# STM32G534 register map
File version: 2.0.0
CPU: CM33 r0p4, little endian, MPU, FPU, 4 interrupt priority bits
Registers are 32-bit, read-write, reset 0x0 unless marked. A register's access mark holds for its fields unless they carry their own. Offsets are from the block's base; [hi:lo] are bit positions; {n}, {i} and the like mark numbered series; 'fields as' and 'values as' point back to an identical list.

## GTZC1_TZSC — GTZC1_TZSC register block
Base 0x40032400
Same registers: GTZC1_TZSC_S 0x50032400
0x00 TZSC_CR — TZSC control register
  [0] LCK — lock the configuration of GTZC1_TZSC_SECCFGRx and GTZC1_TZSC_PRIVCFGRx until next reset
    0=configuration of all GTZC1_TZSC_SECCFGRx and GTZC1_TZSC_PRIVCFGRx not locked; 1=configuration of all GTZC1_TZSC_SECCFGRx and GTZC1_TZSC_PRIVCFGRx locked
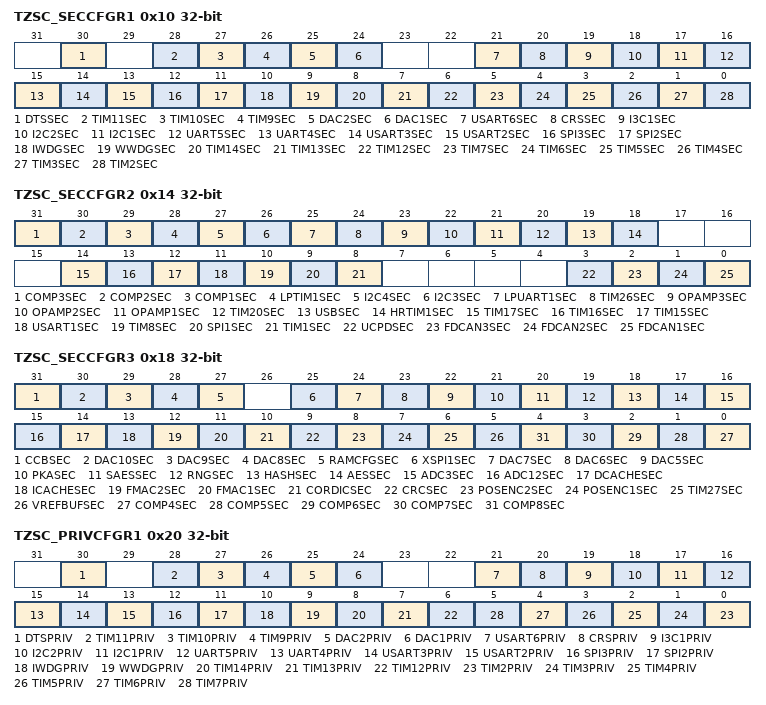
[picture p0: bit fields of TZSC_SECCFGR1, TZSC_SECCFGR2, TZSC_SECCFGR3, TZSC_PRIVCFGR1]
0x10 TZSC_SECCFGR1 — TZSC secure configuration register 1
  [30] DTSSEC — secure access mode for DTS
    0=nonsecure; 1=secure
  [28] TIM11SEC — secure access mode for TIM11
    0=nonsecure; 1=secure
  [27] TIM10SEC — secure access mode for TIM10
    0=nonsecure; 1=secure
  [26] TIM9SEC — secure access mode for TIM9
    0=nonsecure; 1=secure
  [25] DAC2SEC — secure access mode for DAC2
    0=nonsecure; 1=secure
  [24] DAC1SEC — secure access mode for DAC1
    0=nonsecure; 1=secure
  [21] USART6SEC — secure access mode for USART6
    0=nonsecure; 1=secure
  [20] CRSSEC — secure access mode for CRS
    0=nonsecure; 1=secure
  [19] I3C1SEC — secure access mode for I3C1
    0=nonsecure; 1=secure
  [18] I2C2SEC — secure access mode for I2C2
    0=nonsecure; 1=secure
  [17] I2C1SEC — secure access mode for I2C1
    0=nonsecure; 1=secure
  [16] UART5SEC — secure access mode for UART5
    0=nonsecure; 1=secure
  [15] UART4SEC — secure access mode for UART4
    0=nonsecure; 1=secure
  [14] USART3SEC — secure access mode for USART3
    0=nonsecure; 1=securew
  [13] USART2SEC — secure access mode for USART2
    0=nonsecure; 1=secure
  [12] SPI3SEC — secure access mode for SPI3
    0=nonsecure; 1=secure
  [11] SPI2SEC — secure access mode for SPI2
    0=nonsecure; 1=secure
  [10] IWDGSEC — secure access mode for IWDG
    0=nonsecure; 1=secure
  [9] WWDGSEC — secure access mode for WWDG
    0=nonsecure; 1=secure
  [8] TIM14SEC — secure access mode for TIM14
    0=nonsecure; 1=secure
  [7] TIM13SEC — secure access mode for TIM13
    0=nonsecure; 1=secure
  [6] TIM12SEC — secure access mode for TIM12
    0=nonsecure; 1=secure
  [5] TIM7SEC — secure access mode for TIM7
    0=nonsecure; 1=secure
  [4] TIM6SEC — secure access mode for TIM6
    0=nonsecure; 1=secure
  [3] TIM5SEC — secure access mode for TIM5
    0=nonsecure; 1=secure
  [2] TIM4SEC — secure access mode for TIM5
    0=nonsecure; 1=secure
  [1] TIM3SEC — secure access mode for TIM3
    0=nonsecure; 1=secure
  [0] TIM2SEC — secure access mode for TIM2
    0=nonsecure; 1=secure
0x14 TZSC_SECCFGR2 — TZSC secure configuration register 2
  [all] fields
    0=nonsecure; 1=secure
  [31] COMP3SEC — secure access mode for COMP3
  [30] COMP2SEC — secure access mode for COMP2
  [29] COMP1SEC — secure access mode for COMP1
  [28] LPTIM1SEC — secure access mode for LPTIM1
  [27] I2C4SEC — secure access mode for I2C4
  [26] I2C3SEC — secure access mode for I2C3
  [25] LPUART1SEC — secure access mode for LPUART1
  [24] TIM26SEC — secure access mode for TIM26
  [23] OPAMP3SEC — secure access mode for OPAMP3
  [22] OPAMP2SEC — secure access mode for OPAMP2
  [21] OPAMP1SEC — secure access mode for OPAMP1
  [20] TIM20SEC — secure access mode for TIM20
  [19] USBSEC — secure access mode for USB
  [18] HRTIM1SEC — secure access mode for HRTIM1
  [14] TIM17SEC — secure access mode for TIM17
  [13] TIM16SEC — secure access mode for TIM16
  [12] TIM15SEC — secure access mode for TIM15
  [11] USART1SEC — secure access mode for USART1
  [10] TIM8SEC — secure access mode for TIM8
  [9] SPI1SEC — secure access mode for SPI1
  [8] TIM1SEC — secure access mode for TIM1
  [3] UCPDSEC — secure access mode for UCPD
  [2] FDCAN3SEC — secure access mode for FDCAN3
  [1] FDCAN2SEC — secure access mode for FDCAN2
  [0] FDCAN1SEC — secure access mode for FDCAN1
0x18 TZSC_SECCFGR3 — TZSC secure configuration register 3
  [all] fields
    0=nonsecure; 1=secure
  [31] CCBSEC — secure access mode for CCB
  [30] DAC10SEC — secure access mode for DAC10
  [29] DAC9SEC — secure access mode for DAC9
  [28] DAC8SEC — secure access mode for DAC8
  [27] RAMCFGSEC — secure access mode for RAMCFG
  [25] XSPI1SEC — secure access mode for XSPI1
  [24] DAC7SEC — secure access mode for DAC7
  [23] DAC6SEC — secure access mode for DAC6
  [22] DAC5SEC — secure access mode for DAC5
  [21] PKASEC — secure access mode for PKA
  [20] SAESSEC — secure access mode for SAES
  [19] RNGSEC — secure access mode for RNG
  [18] HASHSEC — secure access mode for HASH
  [17] AESSEC — secure access mode for AES
  [16] ADC3SEC — secure access mode for ADC3
  [15] ADC12SEC — secure access mode for ADC1 and ADC2
  [14] DCACHESEC — secure access mode for DCACHE
  [13] ICACHESEC — secure access mode for ICACHE
  [12] FMAC2SEC — secure access mode for register of FMAC2
  [11] FMAC1SEC — secure access mode for register of FMAC1
  [10] CORDICSEC — secure access mode for CORDIC
  [9] CRCSEC — secure access mode for CRC
  [8] POSENC2SEC — secure access mode for POSENC2
  [7] POSENC1SEC — secure access mode for POSENC1
  [6] TIM27SEC — secure access mode for TIM27
  [5] VREFBUFSEC — secure access mode for VREFBUF
  [n-4] COMP{n}SEC (n=4..8) — secure access mode for COMP{n}
0x20 TZSC_PRIVCFGR1 — TZSC privilege configuration register 1
  [all] fields
    0=unprivileged; 1=privileged
  [30] DTSPRIV — privileged access mode for DTS
  [28] TIM11PRIV — privileged access mode for TIM11
  [27] TIM10PRIV — privileged access mode for TIM10
  [26] TIM9PRIV — privileged access mode for TIM9
  [25] DAC2PRIV — privileged access mode for DAC2
  [24] DAC1PRIV — privileged access mode for DAC1
  [21] USART6PRIV — privileged access mode for USART6
  [20] CRSPRIV — privileged access mode for CRS
  [19] I3C1PRIV — privileged access mode for I3C1
  [18] I2C2PRIV — privileged access mode for I2C2
  [17] I2C1PRIV — privileged access mode for I2C1
  [16] UART5PRIV — privileged access mode for UART5
  [15] UART4PRIV — privileged access mode for UART4
  [14] USART3PRIV — privileged access mode for USART3
  [13] USART2PRIV — privileged access mode for USART2
  [12] SPI3PRIV — privileged access mode for SPI3
  [11] SPI2PRIV — privileged access mode for SPI2
  [10] IWDGPRIV — privileged access mode for IWDG
  [9] WWDGPRIV — privileged access mode for WWDG
  [8] TIM14PRIV — privileged access mode for TIM14
  [7] TIM13PRIV — privileged access mode for TIM13
  [6] TIM12PRIV — privileged access mode for TIM12
  [n-2] TIM{n}PRIV (n=2..7) — privileged access mode for TIM{n}
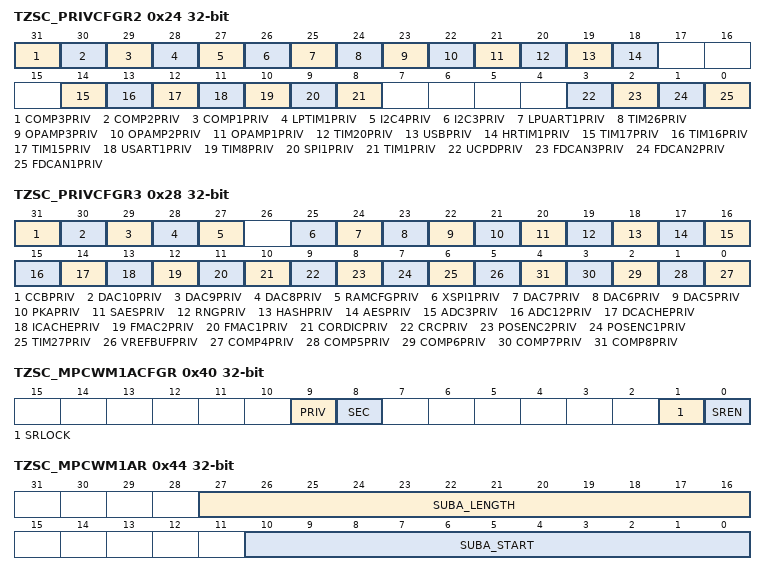
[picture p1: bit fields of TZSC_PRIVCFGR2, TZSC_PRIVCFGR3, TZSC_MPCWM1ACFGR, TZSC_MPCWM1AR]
0x24 TZSC_PRIVCFGR2 — TZSC privilege configuration register 2
  [all] fields
    0=unprivileged; 1=privileged
  [31] COMP3PRIV — privileged access mode for COMP3
  [30] COMP2PRIV — privileged access mode for COMP2
  [29] COMP1PRIV — privileged access mode for COMP1
  [28] LPTIM1PRIV — privileged access mode for LPTIM1
  [27] I2C4PRIV — privileged access mode for I2C4
  [26] I2C3PRIV — privileged access mode for I2C3
  [25] LPUART1PRIV — privileged access mode for LPUART1
  [24] TIM26PRIV — privileged access mode for TIM26
  [23] OPAMP3PRIV — privileged access mode for OPAMP3
  [22] OPAMP2PRIV — privileged access mode for OPAMP2
  [21] OPAMP1PRIV — privileged access mode for OPAMP1
  [20] TIM20PRIV — privileged access mode for TIM20
  [19] USBPRIV — privileged access mode for USB
  [18] HRTIM1PRIV — privileged access mode for HRTIM1
  [14] TIM17PRIV — privileged access mode for TIM17
  [13] TIM16PRIV — privileged access mode for TIM16
  [12] TIM15PRIV — privileged access mode for TIM15
  [11] USART1PRIV — privileged access mode for USART1
  [10] TIM8PRIV — privileged access mode for TIM8
  [9] SPI1PRIV — privileged access mode for SPI1
  [8] TIM1PRIV — privileged access mode for TIM1
  [3] UCPDPRIV — privileged access mode for UCPD
  [2] FDCAN3PRIV — privileged access mode for FDCAN3
  [1] FDCAN2PRIV — privileged access mode for FDCAN2
  [0] FDCAN1PRIV — privileged access mode for FDCAN1
0x28 TZSC_PRIVCFGR3 — TZSC privilege configuration register 3
  [all] fields
    0=unprivileged; 1=privileged
  [31] CCBPRIV — privileged access mode for CCB
  [30] DAC10PRIV — privileged access mode for DAC10
  [29] DAC9PRIV — privileged access mode for DAC9
  [28] DAC8PRIV — privileged access mode for DAC8
  [27] RAMCFGPRIV — privileged access mode for RAMCFG
  [25] XSPI1PRIV — privileged access mode for XSPI1
  [24] DAC7PRIV — privileged access mode for DAC7
  [23] DAC6PRIV — privileged access mode for DAC6
  [22] DAC5PRIV — privileged access mode for DAC5
  [21] PKAPRIV — privileged access mode for PKA
  [20] SAESPRIV — privileged access mode for SAES
  [19] RNGPRIV — privileged access mode for RNG
  [18] HASHPRIV — privileged access mode for HASH
  [17] AESPRIV — privileged access mode for AES
  [16] ADC3PRIV — privileged access mode for ADC3
  [15] ADC12PRIV — privileged access mode for ADC1 and ADC2
  [14] DCACHEPRIV — privileged access mode for DCACHE
  [13] ICACHEPRIV — privileged access mode for ICACHE
  [12] FMAC2PRIV — privileged access mode for register of FMAC2
  [11] FMAC1PRIV — privileged access mode for register of FMAC1
  [10] CORDICPRIV — privileged access mode for CORDIC
  [9] CRCPRIV — privileged access mode for CRC
  [8] POSENC2PRIV — privileged access mode for POSENC2
  [7] POSENC1PRIV — privileged access mode for POSENC1
  [6] TIM27PRIV — privileged access mode for TIM27
  [5] VREFBUFPRIV — privileged access mode for VREFBUF
  [n-4] COMP{n}PRIV (n=4..8) — privileged access mode for COMP{n}
0x40 TZSC_MPCWM1ACFGR — TZSC memory x subregion z watermark configuration register
  [9] PRIV — Privileged subregion z of base region
    0=Privileged and unprivileged accesses are granted in subregion z; 1=Only privileged accesses are granted in subregion z
  [8] SEC — Secure subregion z of base region
    0=Only nonsecure data accesses are granted to subregion z; 1=Only secure data accesses are granted to subregion z
  [1] SRLOCK — subregion z lock
    0=GTZC1_TZSC_MPCWM1CFGR, GTZC1_TZSC_MPCWM1AR and GTZC1_TZSC_MPCWM1BR can be written; 1=Writes to GTZC1_TZSC_MPCWM1CFGR, GTZC1_TZSC_MPCWM1AR and GTZC1_TZSC_MPCWM1BR are ignored
  [0] SREN — subregion z enable
    0=subregion z is disabled; 1=subregion z is enabled
0x44 TZSC_MPCWM1AR — TZSC subregion A watermark register
  [27:16] SUBA_LENGTH — Length of subregion A in base region
  [10:0] SUBA_START — Start of subregion A in base region
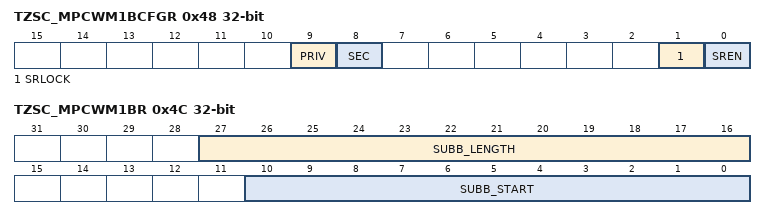
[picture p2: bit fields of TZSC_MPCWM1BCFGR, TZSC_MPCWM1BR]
0x48 TZSC_MPCWM1BCFGR — TZSC memory x subregion z watermark configuration register
  fields as TZSC_MPCWM1ACFGR
0x4C TZSC_MPCWM1BR — TZSC subregion B watermark register
  [27:16] SUBB_LENGTH — Length of subregion B in base region
  [10:0] SUBB_START — Start of subregion B in base region
